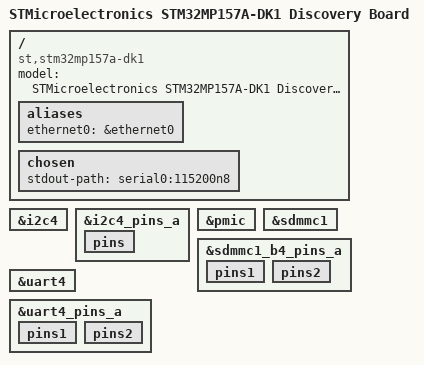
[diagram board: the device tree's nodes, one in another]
// SPDX-License-Identifier: (GPL-2.0+ OR BSD-3-Clause)
/*
 * Copyright (C) STMicroelectronics 2019 - All Rights Reserved
 * Author: Alexandre Torgue <alexandre.torgue@st.com> for STMicroelectronics.
 */

/dts-v1/;

#include "stm32mp157.dtsi"
#include "stm32mp15-pinctrl.dtsi"
#include "stm32mp15xxac-pinctrl.dtsi"
#include "stm32mp15xx-dkx.dtsi"

/ {
	model = "STMicroelectronics STM32MP157A-DK1 Discovery Board";
	compatible = "st,stm32mp157a-dk1", "st,stm32mp157";

	aliases {
		ethernet0 = &ethernet0;
	};

	chosen {
		stdout-path = "serial0:115200n8";
	};
};

&i2c4 {
	bootph-all;
};

&i2c4_pins_a {
	bootph-all;
	pins {
		bootph-all;
	};
};

&pmic {
	bootph-all;
};

&sdmmc1 {
	bootph-pre-ram;
};

&sdmmc1_b4_pins_a {
	bootph-pre-ram;
	pins1 {
		bootph-pre-ram;
	};
	pins2 {
		bootph-pre-ram;
	};
};

&uart4 {
	bootph-all;
};

&uart4_pins_a {
	bootph-all;
	pins1 {
		bootph-all;
	};
	pins2 {
		bootph-all;
	};
};
